# MSS_RCM register map
Vendor: Texas Instruments
Peripheral module from a debugger description file (folder awr2x44p).
Registers are 32-bit, read-write, no defined reset value unless marked. A register's access mark holds for its fields unless they carry their own. Offsets are as the file gives them; lines under a group give offsets from that group; [hi:lo] are bit positions; {n}, {i} and the like mark numbered series; 'fields as' and 'values as' point back to an identical list; <NAME> marks a mode.

## MSS_RCM
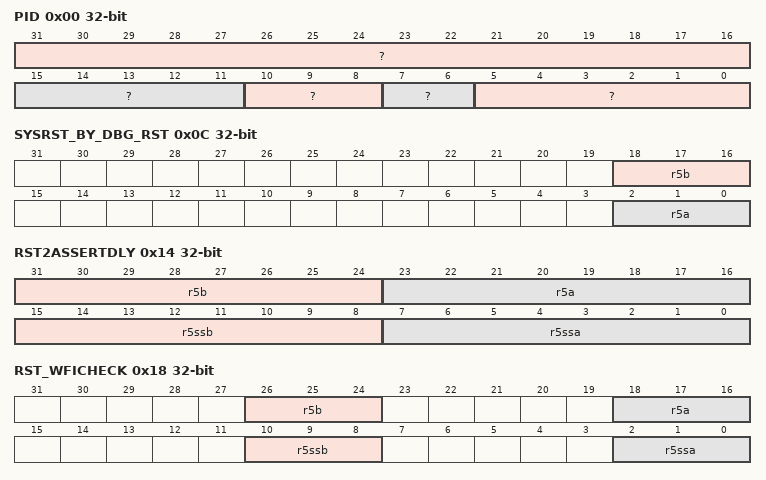
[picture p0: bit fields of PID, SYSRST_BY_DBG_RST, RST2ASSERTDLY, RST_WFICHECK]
0x00 PID ro
  [31:16] ?, [15:11] ?, [10:8] ?, [7:6] ?, [5:0] ?
0x04 MSS_RST_CAUSE_CLR
  [2:0] clr — Write pulse bit field: Clear bit for rst cause register (writing '111' will clear the rst cause register)
0x08 MSS_RST_STATUS ro
  [15:0] cause — Has the status because of which reset has happened. Bit0: POR Reset Bit1: Warm Reset Bit2: STC Reset Bit3 Reset for CR5A and MSS_CR5A_VIM using MSS_RCM::MSS_CR5SSA_RST_CTRL Bit4: Reset for CR5B and MSS_CR5B_VIM using MSS_RCM::MSS_CR5SSB_RST_CTRL Bit5: Reset for CR5A only using MSS_RCM::MSS_CR5A_RST_CTRL Bit6: Reset for CR5B only using using MSS_RCM::MSS_CR5B_RST_CTRL Bit7: Reset for CR5A and MSS_CR5A_VIM caused because of reset request by debugger in CR5A Bit8: Reset for CR5B and MSS_CR5B_VIM caused because of reset request by debugger in CR5B Bit9: Reset for CR5SS by the RESET FSM using MSS_CTRL::R5_CONTROL_RESET_FSM_TRIGGER
0x0C SYSRST_BY_DBG_RST
  [18:16] r5b — writing '111' will block debug reset request from CR5B toggling globally reset for CR5B
  [2:0] r5a — writing '111' will block debug reset request from CR5A toggling globally reset for CR5A
0x10 RST_ASSERDLY
  [7:0] common — Value decides number of cycles reset should be asserted for CR5SS related resets
0x14 RST2ASSERTDLY
  [31:24] r5b — Value decides number of cycles should be held before asserting reset for r5ss local reset for CR5B
  [23:16] r5a — Value decides number of cycles should be held before asserting reset for r5ss local reset for CR5A
  [15:8] r5ssb — Value decides number of cycles should be held before asserting reset for r5ss global reset for CR5B
  [7:0] r5ssa — Value decides number of cycles should be held before asserting reset for r5ss global reset for CR5A.
0x18 RST_WFICHECK
  [26:24] r5b — writing '000' will disable check for WFI before local reset assertion of CR5A
  [18:16] r5a — writing '000' will disable check for WFI before local reset assertion of CR5A
  [10:8] r5ssb — writing '000' will disable check for WFI before global reset assertion of CR5B
  [2:0] r5ssa — writing '000' will disable check for WFI before global reset assertion of CR5A
0x1C MSS_MCANA_CLK_SRC_SEL
  [11:0] clksrcsel — Select line for selecting source clock for MCANA.Data should be loaded as multibit. For example: if '0x5' should be selected then '0x555' should be configured to the register. Refer to TPR12 clock spec for source clock reference
0x20 MSS_MCANB_CLK_SRC_SEL
  [11:0] clksrcsel — Select line for selecting source clock for MCANB.Data should be loaded as multibit. For example: if '0x5' should be selected then '0x555' should be configured to the register. Refer to TPR12 clock spec for source clock reference
0x24 MSS_QSPI_CLK_SRC_SEL
  [11:0] clksrcsel — Select line for selecting source clock for QSPI.Data should be loaded as multibit. For example: if '0x5' should be selected then '0x555' should be configured to the register. Refer to TPR12 clock spec for source clock reference
0x28 MSS_RTIA_CLK_SRC_SEL
  [11:0] clksrcsel — Select line for selecting source clock for RTIA.Data should be loaded as multibit. For example: if '0x5' should be selected then '0x555' should be configured to the register. Refer to TPR12 clock spec for source clock reference
0x2C MSS_RTIB_CLK_SRC_SEL
  [11:0] clksrcsel — Select line for selecting source clock for RTIB.Data should be loaded as multibit. For example: if '0x5' should be selected then '0x555' should be configured to the register. Refer to TPR12 clock spec for source clock reference
0x30 MSS_RTIC_CLK_SRC_SEL
  [11:0] clksrcsel — Select line for selecting source clock for RTIC.Data should be loaded as multibit. For example: if '0x5' should be selected then '0x555' should be configured to the register. Refer to TPR12 clock spec for source clock reference
0x34 MSS_WDT_CLK_SRC_SEL
  [11:0] clksrcsel — Select line for selecting source clock for WDT.Data should be loaded as multibit. For example: if '0x5' should be selected then '0x555' should be configured to the register. Refer to TPR12 clock spec for source clock reference
0x38 MSS_SPIA_CLK_SRC_SEL
  [11:0] clksrcsel — Select line for selecting source clock for SPIA.Data should be loaded as multibit. For example: if '0x5' should be selected then '0x555' should be configured to the register. Refer to TPR12 clock spec for source clock reference
0x3C MSS_SPIB_CLK_SRC_SEL
  [11:0] clksrcsel — Select line for selecting source clock for SPIB.Data should be loaded as multibit. For example: if '0x5' should be selected then '0x555' should be configured to the register. Refer to TPR12 clock spec for source clock reference
0x40 MSS_I2C_CLK_SRC_SEL
  [11:0] clksrcsel — Select line for selecting source clock for I2C.Data should be loaded as multibit. For example: if '0x5' should be selected then '0x555' should be configured to the register. Refer to TPR12 clock spec for source clock reference
0x44 MSS_SCIA_CLK_SRC_SEL
  [11:0] clksrcsel — Select line for selecting source clock for SCIA.Data should be loaded as multibit. For example: if '0x5' should be selected then '0x555' should be configured to the register. Refer to TPR12 clock spec for source clock reference
0x48 MSS_SCIB_CLK_SRC_SEL
  [11:0] clksrcsel — Select line for selecting source clock for SCIB.Data should be loaded as multibit. For example: if '0x5' should be selected then '0x555' should be configured to the register. Refer to TPR12 clock spec for source clock reference
0x4C MSS_CPTS_CLK_SRC_SEL
  [11:0] clksrcsel — Select line for selecting source clock for CPTS.Data should be loaded as multibit. For example: if '0x5' should be selected then '0x555' should be configured to the register. Refer to TPR12 clock spec for source clock reference
0x50 MSS_CPSW_CLK_SRC_SEL
  [11:0] clksrcsel — Select line for selecting source clock for CPSW.Data should be loaded as multibit. For example: if '0x5' should be selected then '0x555' should be configured to the register. Refer to TPR12 clock spec for source clock reference
0x54 MSS_MCANA_CLK_DIV_VAL
  [11:0] clkdivr — Divider value MCANA selected clock.Data should be loaded as multibit. For example: if divider value of 8(1000) should be selected then '100010001000' should be configured to the register. Refer to TPR12 clock planner for clock reference
0x58 MSS_MCANB_CLK_DIV_VAL
  [11:0] clkdivr — Divider value MCANB selected clock.Data should be loaded as multibit. For example: if divider value of '0x8' should be selected then '0x888' should be configured to the register. Refer to TPR12 clock spec for clock reference
0x5C MSS_QSPI_CLK_DIV_VAL
  [11:0] clkdivr — Divider value QSPI selected clock.Data should be loaded as multibit. For example: if divider value of '0x8' should be selected then '0x888' should be configured to the register. Refer to TPR12 clock spec for clock reference
0x60 MSS_RTIA_CLK_DIV_VAL
  [11:0] clkdivr — Divider value RTIA selected clock.Data should be loaded as multibit. For example: if divider value of '0x8' should be selected then '0x888' should be configured to the register. Refer to TPR12 clock spec for clock reference
0x64 MSS_RTIB_CLK_DIV_VAL
  [11:0] clkdivr — Divider value RTIB selected clock.Data should be loaded as multibit. For example: if divider value of '0x8' should be selected then '0x888' should be configured to the register. Refer to TPR12 clock spec for clock reference
0x68 MSS_RTIC_CLK_DIV_VAL
  [11:0] clkdivr — Divider value RTIC selected clock.Data should be loaded as multibit. For example: if divider value of '0x8' should be selected then '0x888' should be configured to the register. Refer to TPR12 clock spec for clock reference
0x6C MSS_WDT_CLK_DIV_VAL
  [11:0] clkdivr — Divider value WDT selected clock.Data should be loaded as multibit. For example: if divider value of '0x8' should be selected then '0x888' should be configured to the register. Refer to TPR12 clock spec for clock reference
0x70 MSS_SPIA_CLK_DIV_VAL
  [11:0] clkdivr — Divider value SPIA selected clock.Data should be loaded as multibit. For example: if divider value of '0x8' should be selected then '0x888' should be configured to the register. Refer to TPR12 clock spec for clock reference
0x74 MSS_SPIB_CLK_DIV_VAL
  [11:0] clkdivr — Divider value SPIB selected clock.Data should be loaded as multibit. For example: if divider value of '0x8' should be selected then '0x888' should be configured to the register. Refer to TPR12 clock spec for clock reference
0x78 MSS_I2C_CLK_DIV_VAL
  [11:0] clkdivr — Divider value I2C selected clock.Data should be loaded as multibit. For example: if divider value of '0x8' should be selected then '0x888' should be configured to the register. Refer to TPR12 clock spec for clock reference
0x7C MSS_SCIA_CLK_DIV_VAL
  [11:0] clkdivr — Divider value SCIA selected clock.Data should be loaded as multibit. For example: if divider value of '0x8' should be selected then '0x888' should be configured to the register. Refer to TPR12 clock spec for clock reference
0x80 MSS_SCIB_CLK_DIV_VAL
  [11:0] clkdivr — Divider value SCIB selected clock.Data should be loaded as multibit. For example: if divider value of '0x8' should be selected then '0x888' should be configured to the register. Refer to TPR12 clock spec for clock reference
0x84 MSS_CPTS_CLK_DIV_VAL
  [11:0] clkdivr — Divider value CPTS selected clock.Data should be loaded as multibit. For example: if divider value of '0x8' should be selected then '0x888' should be configured to the register. Refer to TPR12 clock spec for clock reference
0x88 MSS_CPSW_CLK_DIV_VAL
  [11:0] clkdivr — Divider value CPSW selected clock.Data should be loaded as multibit. For example: if divider value of '0x8' should be selected then '0x888' should be configured to the register. Refer to TPR12 clock spec for clock reference
0x8C MSS_RGMII_CLK_DIV_VAL
  [11:0] clkdivr — Divider value RGMII selected clock.Data should be loaded as multibit. For example: if divider value of '0x8' should be selected then '0x888' should be configured to the register. Refer to TPR12 clock spec for clock reference
0x90 MSS_MII100_CLK_DIV_VAL
  [11:0] clkdivr — Divider value MII100 selected clock.Data should be loaded as multibit. For example: if divider value of '0x8' should be selected then '0x888' should be configured to the register. Refer to TPR12 clock spec for clock reference
0x94 MSS_MII10_CLK_DIV_VAL
  [23:0] clkdivr — Divider value MII10 selected clock.Data should be loaded as multibit. For example: if divider value of '0x8' should be selected then '0x888' should be configured to the register. Refer to TPR12 clock spec for clock reference
0x98 MSS_GPADC_CLK_DIV_VAL
  [23:0] clkdivr — Divider value GPADC selected clock.Data should be loaded as multibit. For example: if divider value of '0x8' should be selected then '0x888' should be configured to the register. Refer to TPR12 clock spec for clock reference
0x9C MSS_MCANA_CLK_GATE
  [2:0] gated — writing '111' will gate clock for MCANA
0xA0 MSS_MCANB_CLK_GATE
  [2:0] gated — writing '111' will gate clock for MCANB
0xA4 MSS_QSPI_CLK_GATE
  [2:0] gated — writing '111' will gate clock for QSPI
0xA8 MSS_RTIA_CLK_GATE
  [2:0] gated — writing '111' will gate clock for RTIA
0xAC MSS_RTIB_CLK_GATE
  [2:0] gated — writing '111' will gate clock for RTIB
0xB0 MSS_RTIC_CLK_GATE
  [2:0] gated — writing '111' will gate clock for RTIC
0xB4 MSS_WDT_CLK_GATE
  [2:0] gated — writing '111' will gate clock for WDT
0xB8 MSS_SPIA_CLK_GATE
  [2:0] gated — writing '111' will gate clock for SPIA
0xBC MSS_SPIB_CLK_GATE
  [2:0] gated — writing '111' will gate clock for SPIB
0xC0 MSS_I2C_CLK_GATE
  [2:0] gated — writing '111' will gate clock for I2C
0xC4 MSS_SCIA_CLK_GATE
  [2:0] gated — writing '111' will gate clock for SCIA
0xC8 MSS_SCIB_CLK_GATE
  [2:0] gated — writing '111' will gate clock for SCIB
0xCC MSS_CPTS_CLK_GATE
  [2:0] gated — writing '111' will gate clock for CPTS
0xD0 MSS_CPSW_CLK_GATE
  [2:0] gated — writing '111' will gate clock for CPSW
0xD4 MSS_RGMII_CLK_GATE
  [2:0] gated — writing '111' will gate clock for RGMII
0xD8 MSS_MII100_CLK_GATE
  [2:0] gated — writing '111' will gate clock for MII100
0xDC MSS_MII10_CLK_GATE
  [2:0] gated — writing '111' will gate clock for MII10
0xE0 MSS_GPADC_CLK_GATE
  [2:0] gated — writing '111' will gate clock for MSS GPADC
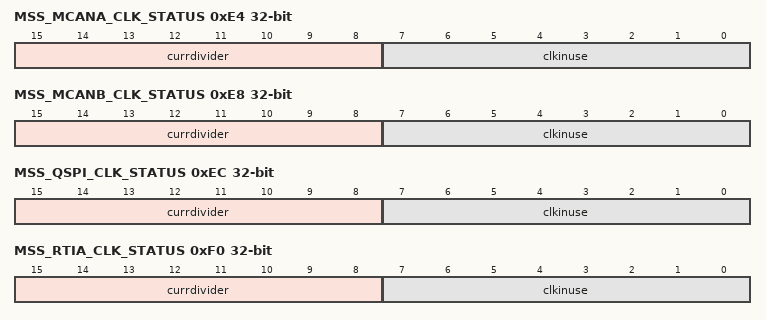
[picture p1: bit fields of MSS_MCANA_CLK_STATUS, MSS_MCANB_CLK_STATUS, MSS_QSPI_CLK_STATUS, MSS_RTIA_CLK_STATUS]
0xE4 MSS_MCANA_CLK_STATUS ro
  [15:8] currdivider — Status shows the current divider value choosen for MCANA
  [7:0] clkinuse — Status shows the source clock slected for MCANA
0xE8 MSS_MCANB_CLK_STATUS ro
  [15:8] currdivider — Status shows the current divider value choosen for MCANB
  [7:0] clkinuse — Status shows the source clock slected for MCANB
0xEC MSS_QSPI_CLK_STATUS ro
  [15:8] currdivider — Status shows the current divider value choosen for QSPI
  [7:0] clkinuse — Status shows the source clock slected for QSPI
0xF0 MSS_RTIA_CLK_STATUS ro
  [15:8] currdivider — Status shows the current divider value choosen for RTIA
  [7:0] clkinuse — Status shows the source clock slected for RTIA
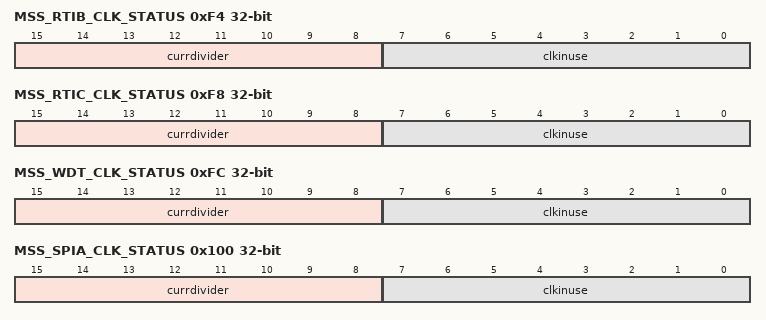
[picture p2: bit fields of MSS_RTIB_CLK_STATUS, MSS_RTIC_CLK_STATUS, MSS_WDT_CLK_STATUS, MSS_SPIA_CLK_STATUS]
0xF4 MSS_RTIB_CLK_STATUS ro
  [15:8] currdivider — Status shows the current divider value choosen for RTIB
  [7:0] clkinuse — Status shows the source clock slected for RTIB
0xF8 MSS_RTIC_CLK_STATUS ro
  [15:8] currdivider — Status shows the current divider value choosen for RTIC
  [7:0] clkinuse — Status shows the source clock slected for RTIC
0xFC MSS_WDT_CLK_STATUS ro
  [15:8] currdivider — Status shows the current divider value choosen for WDT
  [7:0] clkinuse — Status shows the source clock slected for WDT
0x100 MSS_SPIA_CLK_STATUS ro
  [15:8] currdivider — Status shows the current divider value choosen for SPIA
  [7:0] clkinuse — Status shows the source clock slected for SPIA
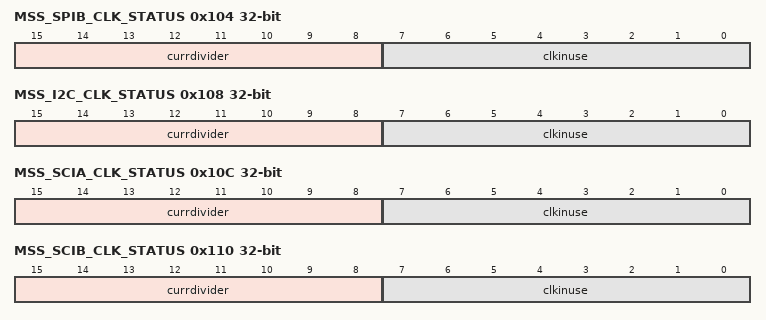
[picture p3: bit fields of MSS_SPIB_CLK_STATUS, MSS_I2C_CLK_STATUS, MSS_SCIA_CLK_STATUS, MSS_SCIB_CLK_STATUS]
0x104 MSS_SPIB_CLK_STATUS ro
  [15:8] currdivider — Status shows the current divider value choosen for SPIB
  [7:0] clkinuse — Status shows the source clock slected for SPIB
0x108 MSS_I2C_CLK_STATUS ro
  [15:8] currdivider — Status shows the current divider value choosen for I2C
  [7:0] clkinuse — Status shows the source clock slected for I2C
0x10C MSS_SCIA_CLK_STATUS ro
  [15:8] currdivider — Status shows the current divider value choosen for SCIA
  [7:0] clkinuse — Status shows the source clock slected for SCIA
0x110 MSS_SCIB_CLK_STATUS ro
  [15:8] currdivider — Status shows the current divider value choosen for SCIB
  [7:0] clkinuse — Status shows the source clock slected for SCIB
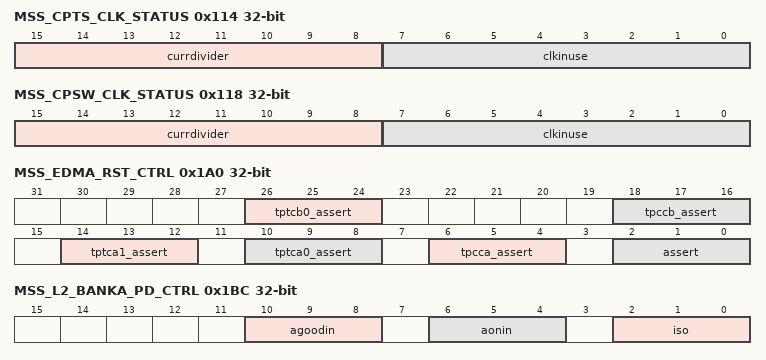
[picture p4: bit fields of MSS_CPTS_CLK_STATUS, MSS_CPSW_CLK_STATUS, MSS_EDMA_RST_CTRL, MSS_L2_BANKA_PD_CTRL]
0x114 MSS_CPTS_CLK_STATUS ro
  [15:8] currdivider — Status shows the current divider value choosen for CPTS
  [7:0] clkinuse — Status shows the source clock slected for CPTS
0x118 MSS_CPSW_CLK_STATUS ro
  [15:8] currdivider — Status shows the current divider value choosen for CPSW
  [7:0] clkinuse — Status shows the source clock slected for CPSW
0x11C MSS_RGMII_CLK_STATUS ro
  [15:8] currdivider — Status shows the current divider value choosen for RGMII
0x120 MSS_MII100_CLK_STATUS ro
  [15:8] currdivider — Status shows the current divider value choosen for MII100
0x124 MSS_MII10_CLK_STATUS ro
  [15:8] currdivider — Status shows the current divider value choosen for MII10
0x128 MSS_GPADC_CLK_STATUS ro
  [15:8] currdivider — Status shows the current divider value choosen for GPADC
0x12C MSS_CR5SS_POR_RST_CTRL
  [2:0] assert — write pulse bit field:This feature is for debug purpose only. Software needs to ensure the state of the Device/IP before configuring. write pulse bit field: writing '111' will assert por reset to R5SS
0x130 MSS_CR5SSA_RST_CTRL
  [2:0] assert — write pulse bit field:This feature is for debug purpose only. Software needs to ensure the state of the Device/IP before configuring. write pulse bit field: writing '111' will reset CR5A and MSS_CR5A_VIM
0x134 MSS_CR5SSB_RST_CTRL
  [2:0] assert — write pulse bit field:This feature is for debug purpose only. Software needs to ensure the state of the Device/IP before configuring. write pulse bit field: writing '111' will reset CR5B and MSS_CR5B_VIM
0x138 MSS_CR5A_RST_CTRL
  [2:0] assert — write pulse bit field:This feature is for debug purpose only. Software needs to ensure the state of the Device/IP before configuring. write pulse bit field: writing '111' will reset CR5A only
0x13C MSS_CR5B_RST_CTRL
  [2:0] assert — write pulse bit field:This feature is for debug purpose only. Software needs to ensure the state of the Device/IP before configuring. write pulse bit field: writing '111' will reset CR5B only
0x140 MSS_VIMA_RST_CTRL
  [2:0] assert — This feature is for debug purpose only. Software needs to ensure the state of the Device/IP before configuring. Writing '111' will reset MSS_CR5A_VIM
0x144 MSS_VIMB_RST_CTRL
  [2:0] assert — This feature is for debug purpose only. Software needs to ensure the state of the Device/IP before configuring. Writing '111' will reset MSS_CR5B_VIM
0x148 MSS_CRC_RST_CTRL
  [2:0] assert — This feature is for debug purpose only. Software needs to ensure the state of the Device/IP before configuring. Writing '111' will reset MCRC
0x14C MSS_RTIA_RST_CTRL
  [2:0] assert — This feature is for debug purpose only. Software needs to ensure the state of the Device/IP before configuring. Writing '111' will reset RTIA
0x150 MSS_RTIB_RST_CTRL
  [2:0] assert — This feature is for debug purpose only. Software needs to ensure the state of the Device/IP before configuring. Writing '111' will reset RTIB
0x154 MSS_RTIC_RST_CTRL
  [2:0] assert — This feature is for debug purpose only. Software needs to ensure the state of the Device/IP before configuring. Writing '111' will reset RTIC
0x158 MSS_WDT_RST_CTRL
  [2:0] assert — This feature is for debug purpose only. Software needs to ensure the state of the Device/IP before configuring. Writing '111' will reset WDT
0x15C MSS_ESM_RST_CTRL
  [2:0] assert — This feature is for debug purpose only. Software needs to ensure the state of the Device/IP before configuring. Writing '111' will reset ESM
0x160 MSS_DCCA_RST_CTRL
  [2:0] assert — This feature is for debug purpose only. Software needs to ensure the state of the Device/IP before configuring. Writing '111' will reset DCCA
0x164 MSS_DCCB_RST_CTRL
  [2:0] assert — This feature is for debug purpose only. Software needs to ensure the state of the Device/IP before configuring. Writing '111' will reset DCCB
0x168 MSS_DCCC_RST_CTRL
  [2:0] assert — This feature is for debug purpose only. Software needs to ensure the state of the Device/IP before configuring. Writing '111' will reset DCCC
0x16C MSS_DCCD_RST_CTRL
  [2:0] assert — This feature is for debug purpose only. Software needs to ensure the state of the Device/IP before configuring. Writing '111' will reset DCCD
0x170 MSS_GIO_RST_CTRL
  [2:0] assert — This feature is for debug purpose only. Software needs to ensure the state of the Device/IP before configuring. Writing '111' will reset GIO
0x174 MSS_SPIA_RST_CTRL
  [2:0] assert — This feature is for debug purpose only. Software needs to ensure the state of the Device/IP before configuring. Writing '111' will reset SPIA
0x178 MSS_SPIB_RST_CTRL
  [2:0] assert — This feature is for debug purpose only. Software needs to ensure the state of the Device/IP before configuring. Writing '111' will reset SPIB
0x17C MSS_QSPI_RST_CTRL
  [2:0] assert — This feature is for debug purpose only. Software needs to ensure the state of the Device/IP before configuring. Writing '111' will reset QSPI
{0x17C+4i} MSS_PWM{i}_RST_CTRL (i=1..3)
  [2:0] assert — This feature is for debug purpose only. Software needs to ensure the state of the Device/IP before configuring. Writing '111' will reset EPWM{i}
0x18C MSS_MCANA_RST_CTRL
  [2:0] assert — This feature is for debug purpose only. Software needs to ensure the state of the Device/IP before configuring. Writing '111' will reset MCANA
0x190 MSS_MCANB_RST_CTRL
  [2:0] assert — This feature is for debug purpose only. Software needs to ensure the state of the Device/IP before configuring. Writing '111' will reset MCANB
0x194 MSS_I2C_RST_CTRL
  [2:0] assert — This feature is for debug purpose only. Software needs to ensure the state of the Device/IP before configuring. Writing '111' will reset I2C
0x198 MSS_SCIA_RST_CTRL
  [2:0] assert — This feature is for debug purpose only. Software needs to ensure the state of the Device/IP before configuring. Writing '111' will reset SCIA
0x19C MSS_SCIB_RST_CTRL
  [2:0] assert — This feature is for debug purpose only. Software needs to ensure the state of the Device/IP before configuring. Writing '111' will reset SCIB
0x1A0 MSS_EDMA_RST_CTRL
  [26:24] tptcb0_assert — This feature is for debug purpose only. Software needs to ensure the state of the Device/IP before configuring. Writing '111' will reset MSS_TPTCB0
  [18:16] tpccb_assert — This feature is for debug purpose only. Software needs to ensure the state of the Device/IP before configuring. Writing '111' will reset MSS_TPCCB
  [14:12] tptca1_assert — This feature is for debug purpose only. Software needs to ensure the state of the Device/IP before configuring. Writing '111' will reset MSS_TPTCA1
  [10:8] tptca0_assert — This feature is for debug purpose only. Software needs to ensure the state of the Device/IP before configuring. Writing '111' will reset MSS_TPTCA0
  [6:4] tpcca_assert — This feature is for debug purpose only. Software needs to ensure the state of the Device/IP before configuring. Writing '111' will reset MSS_TPCCA
  [2:0] assert — This feature is for debug purpose only. Software needs to ensure the state of the Device/IP before configuring. Writing '111' will reset EDMA
0x1A4 MSS_INFRA_RST_CTRL
  [2:0] assert — This feature is for debug purpose only. Software needs to ensure the state of the Device/IP before configuring. Writing '111' will reset MSS INFRA
0x1A8 MSS_CPSW_RST_CTRL
  [2:0] assert — This feature is for debug purpose only. Software needs to ensure the state of the Device/IP before configuring. Writing '111' will reset MSS CPSW
0x1AC MSS_GPADC_RST_CTRL
  [2:0] assert — This feature is for debug purpose only. Software needs to ensure the state of the Device/IP before configuring. Writing '111' will reset MSS GPADC
0x1B0 MSS_DMM_RST_CTRL
  [2:0] assert — This feature is for debug purpose only. Software needs to ensure the state of the Device/IP before configuring. Writing '111' will reset MSS DMMA/B
0x1B4 R5_COREA_GATE
  [2:0] clkgate — writing '111' will gate clock to CR5A related peripherals inside Cortexr5ss
0x1B8 R5_COREB_GATE
  [2:0] clkgate — writing '111' will gate clock to CR5B related peripherals inside Cortexr5ss
0x1BC MSS_L2_BANKA_PD_CTRL
  [10:8] agoodin — SW control for power signal 'AGOODIN' for MSS_L2_BANKA
  [6:4] aonin — SW control for power signal 'AONIN' for MSS_L2_BANKA
  [2:0] iso — SW control for power signal 'ISO' for MSS_L2_BANKA
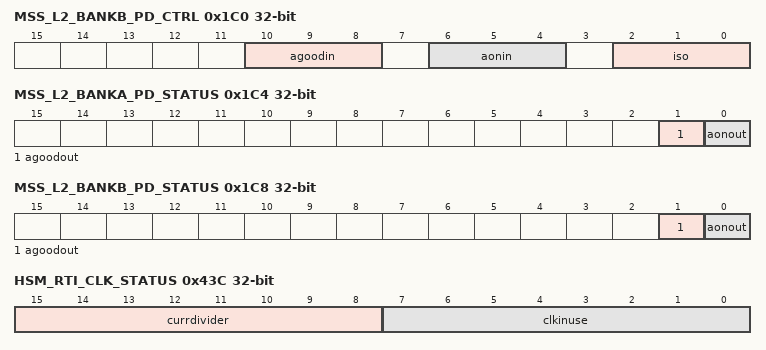
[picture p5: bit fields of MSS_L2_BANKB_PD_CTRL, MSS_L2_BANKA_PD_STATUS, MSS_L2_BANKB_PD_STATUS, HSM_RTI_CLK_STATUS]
0x1C0 MSS_L2_BANKB_PD_CTRL
  [10:8] agoodin — SW control for power signal 'AGOODIN' for MSS_L2_BANKB
  [6:4] aonin — SW control for power signal 'AONIN' for MSS_L2_BANKB
  [2:0] iso — SW control for power signal 'ISO' for MSS_L2_BANKB
0x1C4 MSS_L2_BANKA_PD_STATUS ro
  [1] agoodout — SW status indicating the 'pgoodin' of MSS_L2_BANKA
  [0] aonout — SW status indicating the 'ponin' of MSS_L2_BANKA
0x1C8 MSS_L2_BANKB_PD_STATUS ro
  [1] agoodout — SW status indicating the 'pgoodin' of MSS_L2_BANKB
  [0] aonout — SW status indicating the 'ponin' of MSS_L2_BANKB
0x1CC HW_REG0
  [31:0] hwreg — HW Reserved regiser
0x1D0 HW_REG1
  [31:0] hwreg — HW Reserved regiser
0x1D4 PREVIOUS_NAME
  [31:0] hwreg — HW Reserved regiser
0x1D8 HW_REG3
  [31:0] hwreg — HW Reserved regiser
0x1DC MSS_CR5F_CLK_SRC_SEL_CTRL
  [2:0] clksrcsel — writing 3'b111 ensures R5 to be same as BUS_CLK writing 3'b000 ensures R5 clock will be same as CR5_CLK from top_rcm
0x1E0 MSS_CPSW_MII_CLK_SRC_SEL
  [11:0] clksrcsel — Select line for selecting source clock for CPSW_MII.Data should be loaded as multibit. For example: if '0x5' should be selected then '0x555' should be configured to the register. Refer to TPR12 clock spec for source clock reference
0x1E4 MSS_CPSW_MII_CLK_STATUS ro
  [7:0] clkinuse — Status shows the source clock slected for CPSW_MII
0x400 HSM_RTIA_CLK_SRC_SEL
  [11:0] clksrcsel — Select line for selecting source clock for HSM_RTIA.Data should be loaded as multibit. For example: if '0x5' should be selected then '0x555' should be configured to the register. Refer to TPR12 clock spec for source clock reference
0x404 HSM_WDT_CLK_SRC_SEL
  [11:0] clksrcsel — Select line for selecting source clock for HSM_WDT.Data should be loaded as multibit. For example: if '0x5' should be selected then '0x555' should be configured to the register. Refer to TPR12 clock spec for source clock reference
0x408 HSM_RTC_CLK_SRC_SEL
  [11:0] clksrcsel — Select line for selecting source clock for HSM_RTC.Data should be loaded as multibit. For example: if '0x5' should be selected then '0x555' should be configured to the register. Refer to TPR12 clock spec for source clock reference
0x40C HSM_DMTA_CLK_SRC_SEL
  [11:0] clksrcsel — Select line for selecting source clock for HSM_DMTA.Data should be loaded as multibit. For example: if '0x5' should be selected then '0x555' should be configured to the register. Refer to TPR12 clock spec for source clock reference
0x410 HSM_DMTB_CLK_SRC_SEL
  [11:0] clksrcsel — Select line for selecting source clock for HSM_DMTB.Data should be loaded as multibit. For example: if '0x5' should be selected then '0x555' should be configured to the register. Refer to TPR12 clock spec for source clock reference
0x414 HSM_RTI_CLK_DIV_VAL
  [11:0] clkdivr — Divider value HSM RTI selected clock.Data should be loaded as multibit. For example: if divider value of '0x8' should be selected then '0x888' should be configured to the register. Refer to TPR12 clock spec for clock reference
0x418 HSM_WDT_CLK_DIV_VAL
  [11:0] clkdivr — Divider value HSM WDT selected clock.Data should be loaded as multibit. For example: if divider value of '0x8' should be selected then '0x888' should be configured to the register. Refer to TPR12 clock spec for clock reference
0x41C HSM_RTC_CLK_DIV_VAL
  [11:0] clkdivr — Divider value HSM RTC selected clock.Data should be loaded as multibit. For example: if divider value of '0x8' should be selected then '0x888' should be configured to the register. Refer to TPR12 clock spec for clock reference
0x420 HSM_DMTA_CLK_DIV_VAL
  [11:0] clkdivr — Divider value HSM DMTA selected clock.Data should be loaded as multibit. For example: if divider value of '0x8' should be selected then '0x888' should be configured to the register. Refer to TPR12 clock spec for clock reference
0x424 HSM_DMTB_CLK_DIV_VAL
  [11:0] clkdivr — Divider value HSM DMTB selected clock.Data should be loaded as multibit. For example: if divider value of '0x8' should be selected then '0x888' should be configured to the register. Refer to TPR12 clock spec for clock reference
0x428 HSM_RTI_CLK_GATE
  [2:0] gated — writing '111' will gate clock for HSM RTI
0x42C HSM_WDT_CLK_GATE
  [2:0] gated — writing '111' will gate clock for HSM WDT
0x430 HSM_RTC_CLK_GATE
  [2:0] gated — writing '111' will gate clock for HSM RTC
0x434 HSM_DMTA_CLK_GATE
  [2:0] gated — writing '111' will gate clock for HSM DMTA
0x438 HSM_DMTB_CLK_GATE
  [2:0] gated — writing '111' will gate clock for HSM DMTB
0x43C HSM_RTI_CLK_STATUS ro
  [15:8] currdivider — Status shows the current divider value choosen for HSM_RTI
  [7:0] clkinuse — Status shows the source clock slected for HSM_RTI
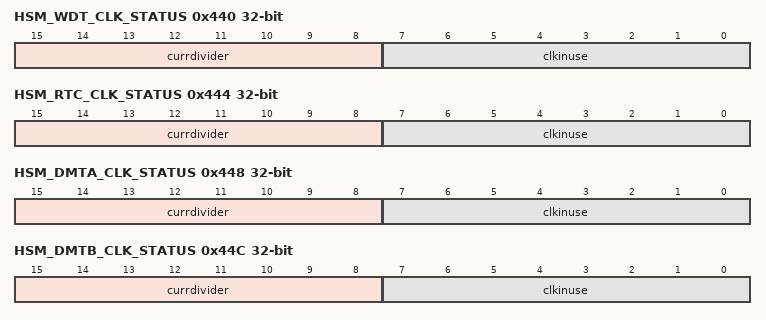
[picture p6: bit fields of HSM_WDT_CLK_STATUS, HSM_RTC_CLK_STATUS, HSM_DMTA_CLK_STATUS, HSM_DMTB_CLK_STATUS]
0x440 HSM_WDT_CLK_STATUS ro
  [15:8] currdivider — Status shows the current divider value choosen for HSM_WDT
  [7:0] clkinuse — Status shows the source clock slected for HSM_WDT
0x444 HSM_RTC_CLK_STATUS ro
  [15:8] currdivider — Status shows the current divider value choosen for HSM_RTC
  [7:0] clkinuse — Status shows the source clock slected for HSM_RTC
0x448 HSM_DMTA_CLK_STATUS ro
  [15:8] currdivider — Status shows the current divider value choosen for HSM_DMTA
  [7:0] clkinuse — Status shows the source clock slected for HSM_DMTA
0x44C HSM_DMTB_CLK_STATUS ro
  [15:8] currdivider — Status shows the current divider value choosen for HSM_DMTB
  [7:0] clkinuse — Status shows the source clock slected for HSM_DMTB
0x450 MSS_CSI2A_RST_CTRL
  [2:0] assert — This feature is for debug purpose only. Software needs to ensure the state of the Device/IP before configuring. Writing '111' will reset MSS CSI2A
0x454 MSS_CSI2A_CLK_GATE
  [2:0] gated — writing '111' will gate clock for MSS CSI2A
{0xFD0+4i} HW_SPARE_RW{i} (i=0..3)
  [31:0] hw_spare_rw{i} — Reserved for HW R&D
{0xFE0+4i} HW_SPARE_RO{i} ro (i=0..3)
  [31:0] hw_spare_ro{i} — Reserved for HW R&D
0xFF0 HW_SPARE_WPH
  [31:0] hw_spare_wph — write pulse bit field:Reserved for HW R&D
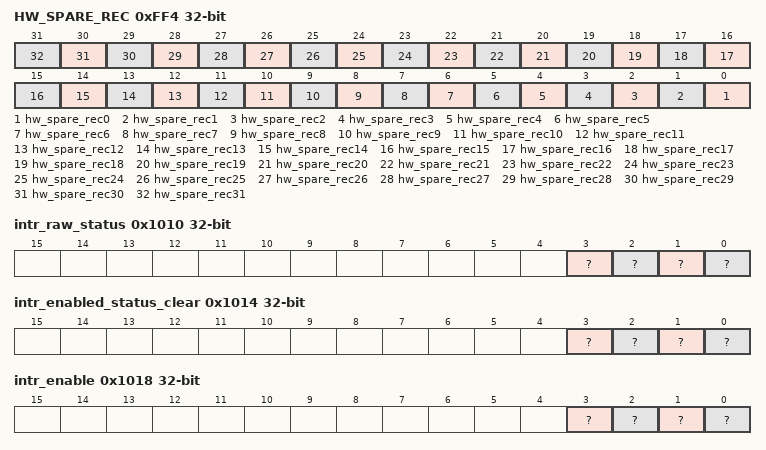
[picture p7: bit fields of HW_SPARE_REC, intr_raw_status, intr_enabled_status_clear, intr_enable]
0xFF4 HW_SPARE_REC
  [n] hw_spare_rec{n} (n=0..31) — Rising Edge Capture reg (write 1 to clear): Reserved for HW R&D
0x1008 LOCK0_KICK0 — - KICK0 component
  [31:0] ?
0x100C LOCK0_KICK1 — - KICK1 component
  [31:0] ?
0x1010 intr_raw_status — Interrupt Raw Status/Set Register
  [3] ? — Proxy0 access violation error. Raw status is read. Write a 1 to set the status. Writing a 0 has no effect.
  [2] ? — Kick access violation error. Raw status is read. Write a 1 to set the status. Writing a 0 has no effect.
  [1] ? — Addressing violation error. Raw status is read. Write a 1 to set the status. Writing a 0 has no effect.
  [0] ? — Protection violation error. Raw status is read. Write a 1 to set the status. Writing a 0 has no effect.
0x1014 intr_enabled_status_clear — Interrupt Enabled Status/Clear register
  [3] ? — Proxy0 access violation error. Enabled status is read. Write a 1 to clear the status. Writing a 0 has no effect.
  [2] ? — Kick access violation error. Enabled status is read. Write a 1 to clear the status. Writing a 0 has no effect.
  [1] ? — Addressing violation error. Enabled status is read. Write a 1 to clear the status. Writing a 0 has no effect.
  [0] ? — Protection violation error. Enabled status is read. Write a 1 to clear the status. Writing a 0 has no effect.
0x1018 intr_enable — Interrupt Enable register
  [3] ? — Proxy0 access violation error enable. Write a 1 to set the enable. Writing a 0 has no effect.
  [2] ? — Kick access violation error enable. Write a 1 to set the enable. Writing a 0 has no effect.
  [1] ? — Addressing violation error enable. Write a 1 to set the enable. Writing a 0 has no effect.
  [0] ? — Protection violation error enable. Write a 1 to set the enable. Writing a 0 has no effect.
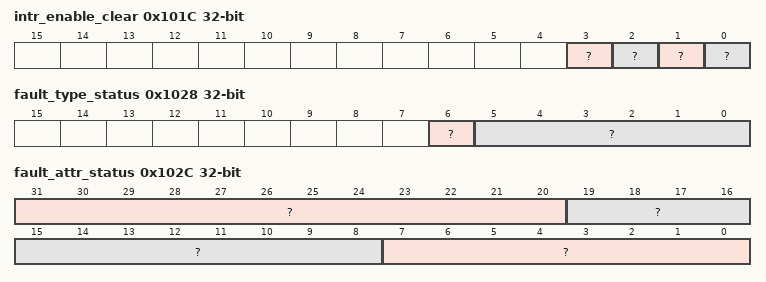
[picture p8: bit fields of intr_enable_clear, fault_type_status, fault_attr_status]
0x101C intr_enable_clear — Interrupt Enable Clear register
  [3] ? — Proxy0 access violation error enable clear. Write a 1 to clear the enable. Writing a 0 has no effect.
  [2] ? — Kick access violation error enable clear. Write a 1 to clear the enable. Writing a 0 has no effect.
  [1] ? — Addressing violation error enable clear. Write a 1 to clear the enable. Writing a 0 has no effect.
  [0] ? — Protection violation error enable clear. Write a 1 to clear the enable. Writing a 0 has no effect.
0x1020 eoi
  [7:0] ? — EOI vector value. Write this with interrupt distribution value in the chip.
0x1024 fault_address ro
  [31:0] ? — Fault Address.
0x1028 fault_type_status ro
  [6] ? — Non-secure access.
  [5:0] ? — Fault Type 10_0000 = Supervisor read fault - priv = 1 dir = 1 dtype != 1 01_0000 = Supervisor write fault - priv = 1 dir = 0 00_1000 = Supervisor execute fault - priv = 1 dir = 1 dtype = 1 00_0100 = User read fault - priv = 0 dir = 1 dtype = 1 00_0010 = User write fault - priv = 0 dir = 0 00_0001 = User execute fault - priv = 0 dir = 1 dtype = 1 00_0000 = No fault
0x102C fault_attr_status ro — Fault Attribute Status register
  [31:20] ? — XID.
  [19:8] ? — Route ID.
  [7:0] ? — Privilege ID.
0x1030 fault_clear wo
  [0] ? — Fault clear. Writing a 1 clears the current fault. Writing a 0 has no effect.
